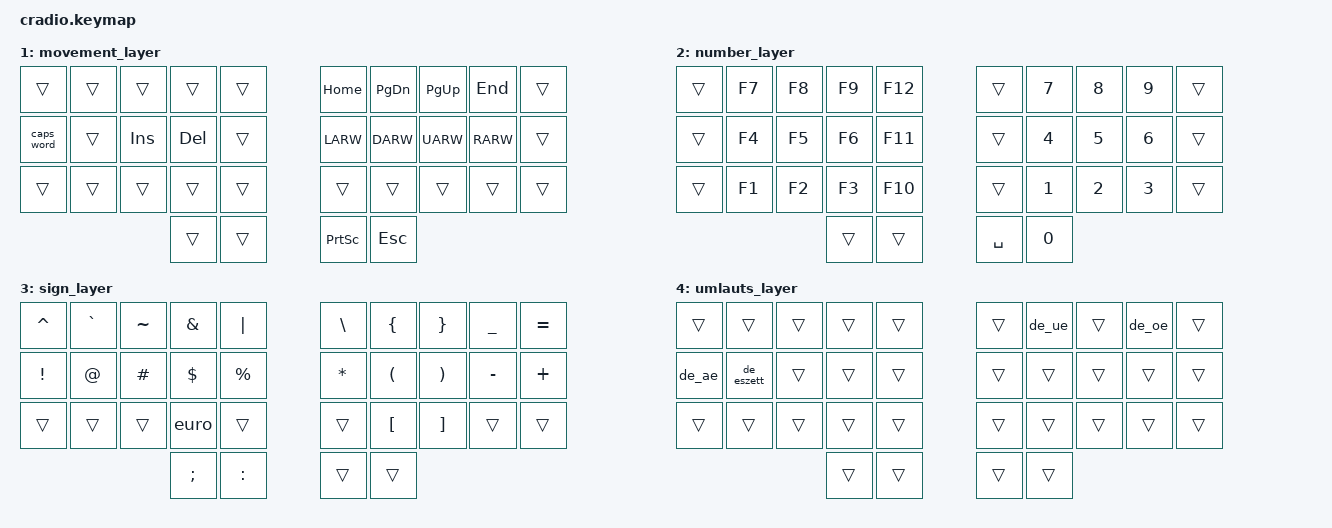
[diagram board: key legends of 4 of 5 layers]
// Copyright (c) 2022 The ZMK Contributors
// SPDX-License-Identifier: MIT

#include <behaviors.dtsi>
#include <dt-bindings/zmk/keys.h>
#include <dt-bindings/zmk/bt.h>

#define HOST_OS 0  // set to 1 for Linux, default is 0 (Windows)
#include "zmk-nodefree-config/helper.h"
#include "zmk-nodefree-config/international_chars/german.dtsi"

// Define euro sign
ZMK_UNICODE_SINGLE(euro, N2, N0, A, C)  // €

// Home row mods macro
#define HRML(k1,k2,k3,k4,k5) &ht LSHFT k1  &ht LALT k2  &ht LCTRL k3  &ht LGUI k4  &ht LSHFT k5
#define HRMR(k1,k2,k3,k4,k5) &ht RSHFT k1  &ht RGUI k2  &ht RCTRL k3  &ht RALT k4  &ht RSHFT k5

/ {
    behaviors {
        ht: hold_tap {
            compatible = "zmk,behavior-hold-tap";
            #binding-cells = <2>;
            flavor = "tap-preferred";
            tapping-term-ms = <220>;
            quick-tap-ms = <150>;
            require-prior-idle-ms = <100>;
            bindings = <&kp>, <&kp>;
        };
    };

    keymap {
        compatible = "zmk,keymap";
        
        default_layer {
            bindings = <
        //╭──────────┬──────────┬──────────┬──────────┬──────────╮   ╭──────────┬──────────┬──────────┬──────────┬──────────╮
        //│  Q       │  W       │  E       │  R       │  T       │   │  Y       │  U       │  I       │  O       │  P       │
            &kp Q      &kp W      &kp E      &kp R      &kp T          &kp Y      &kp U      &kp I      &kp O      &kp P
        //├──────────┼──────────┼──────────┼──────────┼──────────┤   ├──────────┼──────────┼──────────┼──────────┼──────────┤
        //│  A       │  S       │  D       │  F       │  G       │   │  H       │  J       │  K       │  L       │ ' "      │
            HRML(A,     S,         D,         F,         G)            HRMR(H,     J,         K,         L,        SQT)
        //├──────────┼──────────┼──────────┼──────────┼──────────┤   ├──────────┼──────────┼──────────┼──────────┼──────────┤
        //│  Z       │  X       │  C       │  V       │  B       │   │  N       │  M       │ , <      │ . >      │ / ?      │
            &kp Z      &kp X      &kp C      &kp V      &kp B          &kp N      &kp M      &kp COMMA  &kp DOT    &kp FSLH
        //╰──────────┴──────────┴──────────┼──────────┼──────────┤   ├──────────┼──────────┼──────────┴──────────┴──────────╯
        //                                 │ TABULATOR│  ENTER   │   │  SPACE   │ BACKSPACE│
                                            &lt 2 TAB  &lt 1 ENTER    &lt 4 SPACE &lt 3 BSPC
        //                                 ╰──────────┴──────────╯   ╰──────────┴──────────╯
            >;
        };
        
        // Layer 1
		
        movement_layer {
            bindings = <
        //╭──────────┬──────────┬──────────┬──────────┬──────────╮   ╭──────────┬──────────┬──────────┬──────────┬──────────╮
        //│          │          │          │          │          │   │ HOME     │ PAGE DN  │ PAGE UP  │ END      │          │
            &trans     &trans     &trans     &trans     &trans         &kp HOME   &kp PG_DN  &kp PG_UP  &kp END    &trans
        //├──────────┼──────────┼──────────┼──────────┼──────────┤   ├──────────┼──────────┼──────────┼──────────┼──────────┤
        //│ CAPS     │          │ INSERT   │ DELETE   │          │   │ LEFT     │ DOWN     │ UP       │ RIGHT    │          │
           &caps_word  &trans     &kp INS    &kp DEL    &trans         &kp LARW   &kp DARW   &kp UARW   &kp RARW   &trans
        //├──────────┼──────────┼──────────┼──────────┼──────────┤   ├──────────┼──────────┼──────────┼──────────┼──────────┤
        //│          │          │          │          │          │   │          │          │          │          │          │
            &trans     &trans     &trans     &trans     &trans         &trans     &trans     &trans     &trans     &trans
        //╰──────────┴──────────┴──────────┼──────────┼──────────┤   ├──────────┼──────────┼──────────┴──────────┴──────────╯
        //                                 │          │          │   │  DRUCK   │  ESCAPE  │
                                             &trans     &trans        &kp PSCRN   &kp ESC
        //                                 ╰──────────┴──────────╯   ╰──────────┴──────────╯
            >;
        };
        
        // Layer 2
        
        number_layer {
            bindings = <
        //╭──────────┬──────────┬──────────┬──────────┬──────────╮   ╭──────────┬──────────┬──────────┬──────────┬──────────╮
        //│          │  F7      │  F8      │  F9      │  F12     │   │          │  7       │  8       │  9       │          │
            &trans     &kp F7     &kp F8     &kp F9     &kp F12        &trans     &kp N7     &kp N8     &kp N9     &trans
        //├──────────┼──────────┼──────────┼──────────┼──────────┤   ├──────────┼──────────┼──────────┼──────────┼──────────┤
        //│          │  F4      │  F5      │  F6      │  F11     │   │          │  4       │  5       │  6       │          │
            &trans     &kp F4     &kp F5     &kp F6     &kp F11        &trans     &kp N4     &kp N5     &kp N6     &trans
        //├──────────┼──────────┼──────────┼──────────┼──────────┤   ├──────────┼──────────┼──────────┼──────────┼──────────┤
        //│          │  F1      │  F2      │  F3      │  F10     │   │          │  1       │  2       │  3       │          │
            &trans     &kp F1     &kp F2     &kp F3     &kp F10        &trans     &kp N1     &kp N2     &kp N3     &trans
        //╰──────────┴──────────┴──────────┼──────────┼──────────┤   ├──────────┼──────────┼──────────┴──────────┴──────────╯
        //                                 │          │          │   │  SPACE   │  0       │
                                             &trans     &trans         &kp SPACE  &kp N0
        //                                 ╰──────────┴──────────╯   ╰──────────┴──────────╯
            >;
        };
        
        // Layer 3

        sign_layer {
            bindings = <
        //╭──────────┬──────────┬──────────┬──────────┬──────────╮   ╭──────────┬──────────┬──────────┬──────────┬──────────╮
        //│  ^       │  `       │  ~       │  &       │  |       │   │  \       │  {       │  }       │  _       │  =       │
            &kp CARET  &kp GRAVE  &kp TILDE  &kp AMPS   &kp PIPE       &kp BSLH   &kp LBRC   &kp RBRC   &kp UNDER  &kp EQUAL
        //├──────────┼──────────┼──────────┼──────────┼──────────┤   ├──────────┼──────────┼──────────┼──────────┼──────────┤
        //│  !       │  @       │  #       │  $       │  %       │   │  *       │  (       │  )       │  -       │  +       │
            &kp EXCL   &kp AT     &kp HASH   &kp DLLR   &kp PRCNT      &kp ASTRK  &kp LPAR   &kp RPAR   &kp MINUS  &kp PLUS
        //├──────────┼──────────┼──────────┼──────────┼──────────┤   ├──────────┼──────────┼──────────┼──────────┼──────────┤
        //│          │          │          │ EURO     │          │   │          │  [       │  ]       │          │          │
            &trans     &trans     &trans     &euro      &trans         &trans     &kp LBKT   &kp RBKT   &trans     &trans
        //╰──────────┴──────────┴──────────┼──────────┼──────────┤   ├──────────┼──────────┼──────────┴──────────┴──────────╯
        //                                 │  ;       │  :       │   │          │          │
                                             &kp SEMI   &kp COLON      &trans     &trans
        //                                 ╰──────────┴──────────╯   ╰──────────┴──────────╯
            >;
        };
        
        // Layer 4
        
        umlauts_layer {
            bindings = <
        //╭──────────┬──────────┬──────────┬──────────┬──────────╮   ╭──────────┬──────────┬──────────┬──────────┬──────────╮
        //│          │          │          │          │          │   │          │  Ü       │          │  Ö       │          │
            &trans     &trans     &trans     &trans     &trans         &trans     &de_ue     &trans     &de_oe    &trans
        //├──────────┼──────────┼──────────┼──────────┼──────────┤   ├──────────┼──────────┼──────────┼──────────┼──────────┤
        //│  Ä       │  ß       │          │          │          │   │          │          │          │          │          │
            &de_ae    &de_eszett  &trans     &trans     &trans         &trans     &trans     &trans     &trans     &trans
        //├──────────┼──────────┼──────────┼──────────┼──────────┤   ├──────────┼──────────┼──────────┼──────────┼──────────┤
        //│          │          │          │          │          │   │          │          │          │          │          │
            &trans     &trans     &trans     &trans     &trans         &trans     &trans     &trans     &trans     &trans
        //╰──────────┴──────────┴──────────┼──────────┼──────────┤   ├──────────┼──────────┼──────────┴──────────┴──────────╯
        //                                 │          │          │   │          │          │
                                             &trans     &trans         &trans     &trans
        //                                 ╰──────────┴──────────╯   ╰──────────┴──────────╯
            >;
        };
    };
};
/*

//╭──────────┬──────────┬──────────┬──────────┬──────────╮   ╭──────────┬──────────┬──────────┬──────────┬──────────╮
//│          │          │          │          │          │   │          │          │          │          │          │
    &trans     &trans     &trans     &trans     &trans         &trans     &trans     &trans     &trans     &trans
//├──────────┼──────────┼──────────┼──────────┼──────────┤   ├──────────┼──────────┼──────────┼──────────┼──────────┤
//│          │          │          │          │          │   │          │          │          │          │          │
    &trans     &trans     &trans     &trans     &trans         &trans     &trans     &trans     &trans     &trans
//├──────────┼──────────┼──────────┼──────────┼──────────┤   ├──────────┼──────────┼──────────┼──────────┼──────────┤
//│          │          │          │          │          │   │          │          │          │          │          │
    &trans     &trans     &trans     &trans     &trans         &trans     &trans     &trans     &trans     &trans
//╰──────────┴──────────┴──────────┼──────────┼──────────┤   ├──────────┼──────────┼──────────┴──────────┴──────────╯
//                                 │          │          │   │          │          │
                                     &trans     &trans         &trans     &trans
//                                 ╰──────────┴──────────╯   ╰──────────┴──────────╯



conditional_layers {
	compatible = "zmk,conditional-layers";
	tri_layer {
		if-layers = <1 2>;
		then-layer = <3>;
	};
};

tri_layer {
	bindings = <
//╭──────────┬──────────┬──────────┬──────────┬──────────╮   ╭──────────┬──────────┬──────────┬──────────┬──────────╮
//│ RESET    │          │          │          │PROFILE 0 │   │          │          │          │          │  RESET   │
   &sys_reset  &trans     &trans     &trans    &bt BT_SEL 0    &trans     &trans     &trans     &trans    &sys_reset
//├──────────┼──────────┼──────────┼──────────┼──────────┤   ├──────────┼──────────┼──────────┼──────────┼──────────┤
//│BOOTLOADER│          │          │          │PROFILE 1 │   │          │          │          │          │BOOTLOADER│
  &bootloader  &trans     &trans     &trans    &bt BT_SEL 1    &trans     &trans     &trans     &trans    &bootloader
//├──────────┼──────────┼──────────┼──────────┼──────────┤   ├──────────┼──────────┼──────────┼──────────┼──────────┤
//│          │          │          │ CLEAR BT │PROFILE 2 │   │          │          │          │          │          │
    &trans     &trans     &trans    &bt BT_CLR &bt BT_SEL 2    &trans     &trans     &trans     &trans     &trans
//╰──────────┴──────────┴──────────┼──────────┼──────────┤   ├──────────┼──────────┼──────────┴──────────┴──────────╯
                                     &trans     &trans         &trans     &trans
//                                 ╰──────────┴──────────╯   ╰──────────┴──────────╯
	>;
};

*/
